# STM32MP25_CM0P register map
File version: 1.1
CPU: CM0PLUS r0p1, little endian, MPU, no FPU, vendor SysTick, 8 interrupt priority bits
Registers are 32-bit, read-write, reset 0x0 unless marked. A register's access mark holds for its fields unless they carry their own. Offsets are from the block's base; [hi:lo] are bit positions; {n}, {i} and the like mark numbered series; 'fields as' and 'values as' point back to an identical list; <NAME> marks a mode.

## LPDMA — LPDMA register block
Base 0x46210000
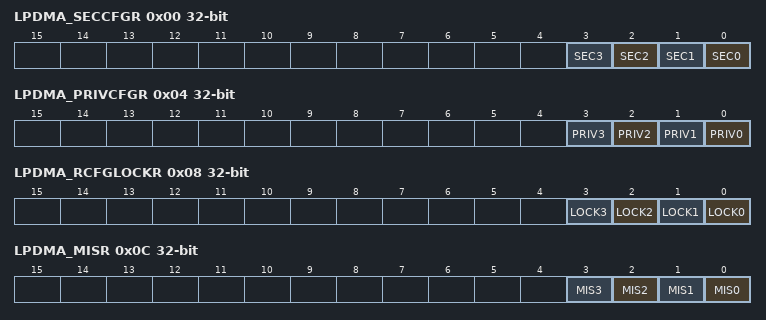
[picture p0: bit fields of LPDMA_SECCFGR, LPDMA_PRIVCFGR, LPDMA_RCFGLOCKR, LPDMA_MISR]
0x00 LPDMA_SECCFGR — LPDMA secure configuration register
  [all] fields
    0=nonsecure; 1=secure
  [n] SEC{n} (n=0..3) — secure state of channel x
0x04 LPDMA_PRIVCFGR — LPDMA privileged configuration register
  [all] fields
    0=unprivileged; 1=privileged
  [n] PRIV{n} (n=0..3) — privileged state of channel x
0x08 LPDMA_RCFGLOCKR — LPDMA configuration lock register
  [all] fields
    0=secure privilege and CID configuration of the channel x is writable; 1=secure privilege and CID configuration of the channel x is not writable
  [n] LOCK{n} (n=0..3) — lock the configuration of LPDMA_SECCFGR.SECx, LPDMA_PRIVCFGR.PRIVx, and LPDMA_CxCIDCFGR until a global DMA reset This bit is cleared after reset and, once set, it cannot be reset until a global DMA reset.
0x0C LPDMA_MISR ro — LPDMA nonsecure masked interrupt status register
  [all] fields
    0=no interrupt occurred on nonsecure channel x; 1=an interrupt occurred on nonsecure channel x
  [n] MIS{n} (n=0..3) — masked interrupt status of channel x
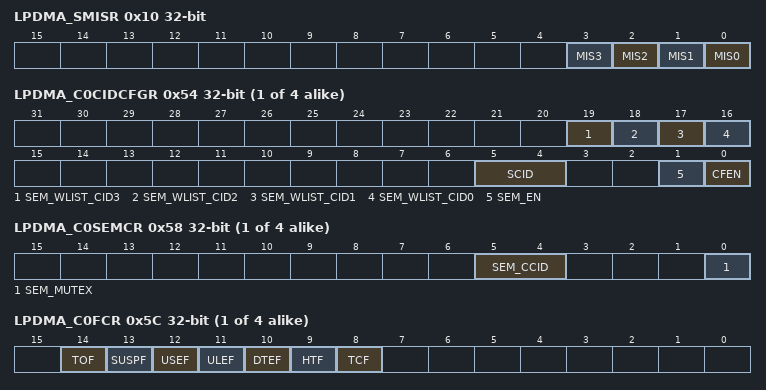
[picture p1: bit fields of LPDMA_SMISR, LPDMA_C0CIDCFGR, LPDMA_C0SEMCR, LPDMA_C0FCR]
0x10 LPDMA_SMISR ro — LPDMA secure masked interrupt status register
  [all] fields
    0=no interrupt occurred on the secure channel x; 1=an interrupt occurred on the secure channel x
  [n] MIS{n} (n=0..3) — masked interrupt status of the secure channel x
{0x50+0x80*i} LPDMA_C{i}LBAR (i=0..3) — LPDMA channel {i} linked-list base address register
  [31:16] LBA — linked-list base address of LPDMA channel x
{0x54+0x80*i} LPDMA_C{i}CIDCFGR (i=0..3) — LPDMA channel {i} CID register
  [19] SEM_WLIST_CID3 — white-listed CID3 in the CID allocation pool (of channel x in semaphoremode)
    0=CID3 black-listed in the CID allocation pool (of channel x in semaphore mode); 1=CID3 white-listed in the CID allocation pool (of channel x in semaphore mode)
  [18] SEM_WLIST_CID2 — white-listed CID2 in the CID allocation pool (of channel x in semaphoremode)
    0=CID2 black-listed in the CID allocation pool (of channel x in semaphore mode); 1=CID2 white-listed in the CID allocation pool (of channel x in semaphore mode)
  [17] SEM_WLIST_CID1 — white-listed CID1 in the CID allocation pool (of channel x in semaphoremode)
    0=CID1 black-listed in the CID allocation pool (of the channel x in semaphore mode); 1=CID1 white-listed in the CID allocation pool (of the channel x in semaphore mode)
  [16] SEM_WLIST_CID0 — white-listed CID0 in the CID allocation pool (of channel x in semaphoremode)
    0=CID0 black-listed in the CID allocation pool (of channel x in semaphore mode); 1=CID0 white-listed in the CID allocation pool (of channel x in semaphore mode)
  [5:4] SCID — static CID selection to channel x
    0=CID0 allocated to channel x; 1=CID1 allocated to channel x; 2=CID2 statically allocated to channel x; 3=CID3 allocated to channel x
  [1] SEM_EN — semaphore mode enable (for the CID allocation policy to the channel x) Note: If SEM_EN=1 and if a trusted domain or debug domain CID agent clears this bit, then the LPDMA hardware automatically clears the LPDMA_CxSEMCR.SEM_MUTEX.
    0=semaphore mode disabled. CID allocation policy to the channel x is defined by SCID[1:0].; 1=semaphore mode enabled. CID allocation policy to the channel x is defined by the white listed allocation pool SEM_WLIST_CIDx and LPDMA_CxSEMCR.SEM_MUTEX.
  [0] CFEN — CID filtering enable of the channel x Note: If SCFEN=1 and if a trusted domain or debug domain CID agent clears this bit, then the LPDMA hardware automatically clears the LPDMA_CxSEMCR.SEM_MUTEX.
    0=CID filtering disabled for when accessing a channel x register/field; 1=CID filtering enabled for when accessing a channel x register/field
{0x58+0x80*i} LPDMA_C{i}SEMCR (i=0..3) — LPDMA channel {i} semaphore control register
  [5:4] SEM_CCID ro — current CID allocated to channel x in semaphore mode This read-only field is internally updated when a white-listed CID takes the control of channel x, in semaphore mode. If SEM_MUTEX=0, this same CID also released it.
    0=CID0 is the last white-listed CID that took the control of channel x; 1=CID1 is the last white-listed CID that took the control of channel x; 2=CID2 is the last white-listed CID that took the control of channel x; 3=CID3 is the last white-listed CID that took the control of the channel x
  [0] SEM_MUTEX — mutex exclusion semaphore for the CID allocation of channel x (insemaphoremode) If the channel x is in secure state (LPDMA_SECCFGR.SECx=1), this bit can only be written by a secure agent. If the channel x is in privileged state (LPDMA_PRIVCFGR.PRIVx=1), this bit can only be written by a privileged agent. If the channel x is CID-filtered (LPDMA_CxCIDCFGR.CFEN=1) and in semaphore mode (LPDMA_CIDCFGR.SEM_EN=1), this bit can only be written either by an authorized (white-listed) CID agent to take the control, or by the same (white-listed) CID agent to release the control. Condition 'On write': Condition 'On read': Note: This bit must be written when LPDMA_CxCR.EN=0. This bit is read-only when LPDMA_CxCR.EN=1. Note: When EN of CFEN bit is cleared in LPDMA_CxSEMCR, the LPDMA hardware automatically clears this SEM_MUTEX bit.
    0=channel x CID-free (not currently under the control of any white-listed CID); 1=channel x CID-allocated (currently taken and under the control of one white-listed CID)
{0x5C+0x80*i} LPDMA_C{i}FCR wo (i=0..3) — LPDMA channel {i} flag clear register
  [14] TOF — trigger overrun flag clear
    0=no effect; 1=clears the corresponding TOF flag
  [13] SUSPF — completed suspension flag clear
    0=no effect; 1=corresponding SUSPF flag cleared
  [12] USEF — user setting error flag clear
    0=no effect; 1=corresponding USEF flag cleared
  [11] ULEF — update link transfer error flag clear
    0=no effect; 1=corresponding ULEF flag cleared
  [10] DTEF — data transfer error flag clear
    0=no effect; 1=corresponding DTEF flag cleared
  [9] HTF — half transfer flag clear
    0=no effect; 1=corresponding HTF flag cleared
  [8] TCF — transfer complete flag clear
    0=no effect; 1=corresponding TCF flag cleared
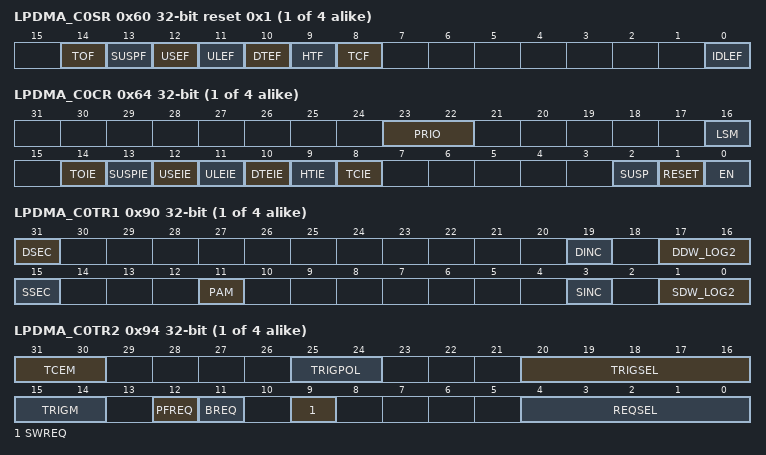
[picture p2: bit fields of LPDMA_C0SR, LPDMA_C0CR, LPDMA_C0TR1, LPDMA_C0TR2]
{0x60+0x80*i} LPDMA_C{i}SR ro reset 0x1 (i=0..3) — LPDMA channel {i} status register
  [14] TOF — trigger overrun flag clear
    0=no effect; 1=clears the corresponding TOF flag
  [13] SUSPF — completed suspension flag
    0=no completed suspension event; 1=a completed suspension event occurred
  [12] USEF — user setting error flag
    0=no user setting error event; 1=a user setting error event occurred
  [11] ULEF — update link transfer error flag
    0=no update link transfer error event; 1=a master bus error event occurred while updating a linked-list register from memory
  [10] DTEF — data transfer error flag
    0=no data transfer error event; 1=a master bus error event occurred on a data transfer
  [9] HTF — half transfer flag A half transfer event is a half block transfer that occurs when half of the bytes of the source block size (rounded-up integer of LPDMA_CxBR1.BNDT[15:0]/2) has been transferred to the destination.
    0=no half transfer event; 1=a half transfer event occurred
  [8] TCF — transfer complete flag A transfer complete event is a block transfer complete or a LLI transfer complete including the upload of the next LLI if any, or the full linked-list completion, depending on the transfer complete event mode LPDMA_CxTR2.TCEM[1:0].
    0=no transfer complete event; 1=a transfer complete event occurred
  [0] IDLEF — idle flag This idle flag is de-asserted by hardware when the channel is enabled (LPDMA_CxCR.EN=1) with a valid channel configuration (no USEF to be immediately reported). This idle flag is asserted after hard reset or by hardware when the channel is back in idle state (in suspended or disabled state).
    0=channel not in idle state; 1=channel in idle state
{0x64+0x80*i} LPDMA_C{i}CR (i=0..3) — LPDMA channel {i} control register
  [23:22] PRIO — priority level of the channel x LPDMA transfer versus others Note: This bit must be written when EN=0. This bit is read-only when EN=1.
    0=low priority, low weight; 1=low priority, mid weight; 2=low priority, high weight; 3=high priority
  [16] LSM — Link step mode First the block transfer is executed as defined by the current internal register file until LPDMA_CxBR1.BNDT[15:0]=0). Secondly the next linked-list data structure is conditionally uploaded from memory as defined by LPDMA_CxLLR. Then channel execution is completed. Note: This bit must be written when EN=0. This bit is read-only when EN=1.
    0=channel executed for the full linked-list and completed at the end of the last LLI (LPDMA_CxLLR=0). The 16 low-significant bits of the link address are null (LA[15:0]=0) and all the update bits are null (UT1=UB1=UT2=USA=UDA=ULL=0). Then LPDMA_CxBR1.BNDT[15:0]=0.; 1=channel executed once for the current LLI
  [14] TOIE — trigger overrun interrupt enable
    0=interrupt disabled; 1=interrupt enabled
  [13] SUSPIE — completed suspension interrupt enable
    0=interrupt disabled; 1=interrupt enabled
  [12] USEIE — user setting error interrupt enable
    0=interrupt disabled; 1=interrupt enabled
  [11] ULEIE — update link transfer error interrupt enable
    0=interrupt disabled; 1=interrupt enabled
  [10] DTEIE — data transfer error interrupt enable
    0=interrupt disabled; 1=interrupt enabled
  [9] HTIE — half transfer complete interrupt enable
    0=interrupt disabled; 1=interrupt enabled
  [8] TCIE — transfer complete interrupt enable
    0=interrupt disabled; 1=interrupt enabled
  [2] SUSP — suspend Writing 1 into the field RESET (bit 1) causes the hardware to de-assert this bit, whatever is written into this bit 2. Else: Software must write 1 in order to suspend an active channel (with an ongoing DMA transfer over its master ports). The software must write 0 in order to resume a suspended channel, following the programming sequence detailed in Figure178.
    0=write: resume channel, read: channel not suspended; 1=write: suspend channel, read: channel suspended
  [1] RESET wo — reset This bit is write only. Writing 0 has no impact. Writing 1 implies the reset of the following: the channel internal state, SUSP and EN bits (whatever is written receptively in bit 2 and bit 0). The reset is effective when the channel is in steady state, meaning one of the following: - active channel in suspended state (LPDMA_CxSR.SUSPF=1 and LPDMA_CxSR.IDLEF=LPDMA_CxCR.EN=1) - channel in disabled state (LPDMA_CxSR.IDLEF=1 and LPDMA_CxCR.EN=0). After writing a RESET, to continue using this channel, the user must explicitly reconfigure the channel including the hardware-modified configuration registers (LPDMA_CxBR1, LPDMA_CxSAR and LPDMA_CxDAR) before enabling again the channel (see the programming sequence in Figure179).
    0=no channel reset; 1=channel reset
  [0] EN — enable Writing 1 into the field RESET (bit 1) causes the hardware to de-assert this bit, whatever is written into this bit 0. Else: this bit is de-asserted by hardware when there is a transfer error (master bus error or user setting error) or when there is a channel transfer complete (channel ready to be configured, for example: if LSM = 1 at the end of a single execution of the LLI). Else, this bit can be asserted by software. Writing 0 into this EN bit is ignored.
    0=write: ignored, read: channel disabled; 1=write: enable channel, read: channel enabled
{0x90+0x80*i} LPDMA_C{i}TR1 (i=0..3) — LPDMA channel {i} transfer register 1
  [31] DSEC — security attribute of the LPDMA transfer to the destination If LPDMA_SECCFGR.SECx=1 and the access is secure: This is a secure register bit. This bit can only be read by a secure software. This bit must be written by a secure software when LPDMA_SECCFGR.SECx=1. A secure write is ignored when LPDMA_SECCFGR.SECx=0. When LPDMA_SECCFGR.SECx is de-asserted, this DSEC bit is also de-asserted by hardware (on a secure reconfiguration of the channel as nonsecure), and the LPDMA transfer to the destination is nonsecure.
    0=LPDMA transfer nonsecure; 1=LPDMA transfer secure
  [19] DINC — destination incrementing single The destination address, pointed by LPDMA_CxDAR, is kept constant after a single transfer, or is incremented by the offset value corresponding to a contiguous data after a single transfer.
    0=fixed single; 1=contiguously incremented single
  [17:16] DDW_LOG2 — binary logarithm of the destination data width of a single in bytes Setting a 8-byte data width causes a user setting error to be reported and none transfer is issued. Note: A destination single transfer must have an aligned address with its data width (start address LPDMA_CxDAR[2:0] versus DDW_LOG2[1:0]). Otherwise a user setting error is reported and none transfer is issued.
    0=byte; 1=half-word (2 bytes); 2=word (4 bytes); 3=user setting error reported and no transfer issued
  [15] SSEC — security attribute of the LPDMA transfer from the source If LPDMA_SECCFGR.SECx=1 and the access is secure: This is a secure register bit. This bit can only be read by a secure software. This bit must be written by a secure software when LPDMA_SECCFGR.SECx=1. A secure write is ignored when LPDMA_SECCFGR.SECx=0. When LPDMA_SECCFGR.SECx is de-asserted, this SSEC bit is also de-asserted by hardware (on a secure reconfiguration of the channel as nonsecure), and the LPDMA transfer from the source is nonsecure.
    0=LPDMA transfer nonsecure; 1=LPDMA transfer secure
  [11] PAM — padding/alignment mode If DDW_LOG2[1:0] = SDW_LOG2[1:0]: if the data width of a single destination transfer is equal to the data width of a single source transfer, this bit is ignored. Else, in the following enumerated values, the condition PAM_1 is when destination data width is higher that source data width, and the condition PAM_2 is when destination data width is higher than source data width.
    0=B_0x0_PAM_1 (source data is transferred as right aligned, padded with 0s up to the destination data width); 1=B_0x1_PAM_1 (source data is transferred as right aligned, sign extended up to the destination data width)
  [3] SINC — source incrementing single The source address, pointed by LPDMA_CxSAR, is kept constant after a single transfer or is incremented by the offset value corresponding to a contiguous data after a single transfer.
    0=fixed single; 1=contiguously incremented single
  [1:0] SDW_LOG2 — binary logarithm of the source data width of a single in bytes Setting a 8-byte data width causes a user setting error to be reported and none transfer is issued. a source block size must be a multiple of the source data width (LPDMA_CxBR1.BNDT[2:0] versus SDW_LOG2[1:0]). Otherwise, a user setting error is reported and no transfer is issued. Note: A source single transfer must have an aligned address with its data width (start address LPDMA_CxSAR[2:0] versus SDW_LOG2[1:0]). Otherwise, a user setting error is reported and none transfer is issued.
    values as DDW_LOG2
{0x94+0x80*i} LPDMA_C{i}TR2 (i=0..3) — LPDMA channel {i} transfer register 2
  [31:30] TCEM — transfer complete event mode These bits define the transfer granularity for the transfer complete and half transfer complete events generation. Note: If the initial LLI<sub>0 </sub>data transfer is null/void (directly programmed by the internal register file with LPDMA_CxBR1.BNDT[15:0]=0), then neither the complete transfer event nor the half transfer event is generated. Note: If the initial LLI<sub>0 </sub>data transfer is null/void (i.e. directly programmed by the internal register file with LPDMA_CxBR1.BNDT[15:0]= 0), then the half transfer event is not generated, and the transfer complete event is generated when is completed the loading of the LLI<sub>1</sub>.
    0=at block level (when LPDMA_CxBR1.BNDT[15:0]=0): the complete (and the half) transfer event is generated at the (respectively half of the) end of a block; 1=same as 00; 2=at LLI level: the complete transfer event is generated at the end of the LLI transfer, including the update of the LLI if any. The half transfer event is generated at the half of the LLI data transfer (the LLI data transfer being a block transfer), if any data transfer.; 3=at channel level: the complete transfer event is generated at the end of the last LLI transfer. The half transfer event is generated at the half of the data transfer of the last LLI. The last LLI updates the link address LPDMA_CxLLR.LA[15:2] to zero and clears all the LPDMA_CxLLR update bits (UT1, UT2, UB1, USA, UDA and ULL). If the channel transfer is continuous/infinite, no event is generated.
  [25:24] TRIGPOL — trigger event polarity These bits define the polarity of the selected trigger event input defined by TRIGSEL[4:0].
    0=no trigger (masked trigger event); 1=trigger on the rising edge; 2=trigger on the falling edge; 3=same as 00
  [20:16] TRIGSEL — trigger event input selection These bits select the trigger event input of the LPDMA transfer (as perSection27.3.6), with an active trigger event if TRIGPOL[1:0]=00.
  [15:14] TRIGM — trigger mode These bits define the transfer granularity for its conditioning by the trigger. If the channel x is enabled (LPDMA_CxCR.EN asserted) with TRIGPOL[1:0]=0b00 or 0b11, these TRIGM[1:0] bits are ignored. Else, a DMA transfer is conditioned by at least one trigger hit: The LPDMA monitoring of a trigger for channel x is started when the channel is enabled/loaded with a new active trigger configuration: rising or falling edge on a selected trigger (TRIGPOL[1:0]=0b01 or respectively TRIGPOL[1:0]=0b10). The monitoring of this trigger is kept active during the triggered and uncompleted (data or link) transfer; and if a new trigger is detected then, this hit is internally memorized to grant the next transfer, as long as the defined rising or falling edge is not modified, and the TRIGSEL[4:0] is not modified, and the channel is enabled. Transferring a next LLI<sub>n+1</sub> that updates the LPDMA_CxTR2 with a new value for any of TRIGSEL[4:0] or TRIGPOL[1:0], resets the monitoring, trashing the memorized hit of the formerly defined LLI<sub>n </sub>trigger. After a first new trigger hit<sub>n+1</sub> is memorized, if another second trigger hit<sub>n+2</sub> is detected and if the hit<sub>n</sub> triggered transfer is still not completed, hit<sub>n+2 </sub>is lost and not memorized, and a trigger overrun flag is reported (LPDMA_CxSR.TOF=1), an interrupt is generated if enabled (LPDMA_CxCR.TOIE=1). The channel is not automatically disabled by hardware due to a trigger overrun.
    0=at block level: the first single read of each block transfer is conditioned by one hit trigger; 1=same as 00; 2=at link level: a LLI link transfer is conditioned by one hit trigger. The LLI data transfer (if any) is not conditioned.; 3=at programmed single level: each programmed single read is conditioned by one hit trigger
  [12] PFREQ — Hardware request in peripheral flow control mode Important: If a given channel x is not implemented with this feature, this bit is reserved and PFREQ is not present (see Section27.3.5 for the list of the implemented channels with this feature. If the channel x is activated (LPDMA_CxCR.EN asserted) with SWREQ=1 (software request for a memory-to-memory transfer), this bit is ignored. Else:
    0=the selected hardware request is driven by a peripheral with a hardware request/acknowledge protocol in LPDMA control mode. The LPDMA is programmed with LPDMA_CxCBR1.BNDT[15:0] and this is internally used by the hardware for the block transfer completion.; 1=the selected hardware request is driven by a peripheral with a hardware request/acknowledge protocol in peripheral control mode. The LPDMA block transfer can be early completed by the peripheral itself (see Section27.3.5 for more details).
  [11] BREQ — block hardware request If the channel x is activated (LPDMA_CxCR.EN asserted) with SWREQ = 1 (software request for a memory-to-memory transfer), this bit is ignored. Else:
    0=the selected hardware request is driven by a peripheral with a hardware request/acknowledge protocol at a single level; 1=the selected hardware request is driven by a peripheral with a hardware request/acknowledge protocol at a block level (seeSection27.3.4)
  [9] SWREQ — software request This bit is internally taken into account when LPDMA_CxCR.EN is asserted.
    0=no software request. The selected hardware request REQSEL[4:0] is taken into account.; 1=software request for a memory-to-memory transfer. The default selected hardware request as per REQSEL[4:0] is ignored.
  [4:0] REQSEL — DMA hardware request selection These bits are ignored if channel x is activated (LPDMA_CxCR.EN asserted) with SWREQ=1 (software request for a memory-to-memory transfer). Else, the selected hardware request is internally taken into account as per Section27.3.3. The user must not assign a same input hardware request (same REQSEL[4:0] value) to different active DMA channels (LPDMA_CxCR.EN=1 and LPDMA_CxTR2.SWREQ=0 for these channels). DMA is not intended to hardware support the case of simultaneous enabled channels incorrectly configured with a same hardware peripheral request signal, and there is no user setting error reporting.
{0x98+0x80*i} LPDMA_C{i}BR1 (i=0..3) — LPDMA channel {i} block register 1
  [15:0] BNDT — block number of data bytes to transfer from the source Block size transferred from the source. When the channel is enabled, this field becomes read-only and is decremented, indicating the remaining number of data items in the current source block to be transferred. BNDT[15:0] is programmed in number of bytes, maximum source block size is 64Kbytes -1. Once the last data transfer is completed (BNDT[15:0]=0): - if LPDMA_CxLLR.UB1=1, this field is updated by the LLI in the memory. - if LPDMA_CxLLR.UB1=0 and if there is at least one non null Uxx update bit, this field is internally restored to the programmed value. - if all LPDMA_CxLLR.Uxx=0 and if LPDMA_CxLLR.LA[15:0]=0, this field is internally restored to the programmed value (infinite/continuous last LLI). - if LPDMA_CxLLR=0, this field is kept as zero following the last LLI data transfer. Note: A non-null source block size must be a multiple of the source data width (BNDT[2:0] versus LPDMA_CxTR1.SDW_LOG2[1:0]). Else a user setting error is reported and none transfer is issued.
{0x9C+0x80*i} LPDMA_C{i}SAR (i=0..3) — LPDMA channel {i} source address register
  [31:0] SA — source address This field is the pointer to the address from which the next data is read. During the channel activity, depending on the source addressing mode (LPDMA_CxTR1.SINC), this field is either kept fixed or incremented by the data width (LPDMA_CxTR1.SDW_LOG2[1:0]) after each single source data, reflecting the next address from which data is read. In linked-list mode, after a LLI data transfer is completed, this register is automatically updated by LPDMA from the memory, provided the LLI is set with LPDMA_CxLLR.USA=1. Note: A source address must be aligned with the programmed data width of a source single (SA[32:0] versus LPDMA_CxTR1.SDW_LOG2[1:0]). Else, a user setting error is reported and no transfer is issued.
{0xA0+0x80*i} LPDMA_C{i}DAR (i=0..3) — LPDMA channel {i} destination address register
  [31:0] DA — destination address This field is the pointer to the address from which the next data is written. During the channel activity, depending on the destination addressing mode (LPDMA_CxTR1.DINC), this field is kept fixed or incremented by the data width (LPDMA_CxTR1.DDW_LOG2[1:0]) after each single destination data, reflecting the next address from which data is written. In linked-list mode, after a LLI data transfer is completed, this register is automatically updated by DMA from the memory, provided the LLI is set with LPDMA_CxLLR.UDA=1. Note: A destination address must be aligned with the programmed data width of a destination single (DA[2:0] versus LPDMA_CxTR1.DDW_LOG2[1:0]). Else, a user setting error is reported and no transfer is issued.
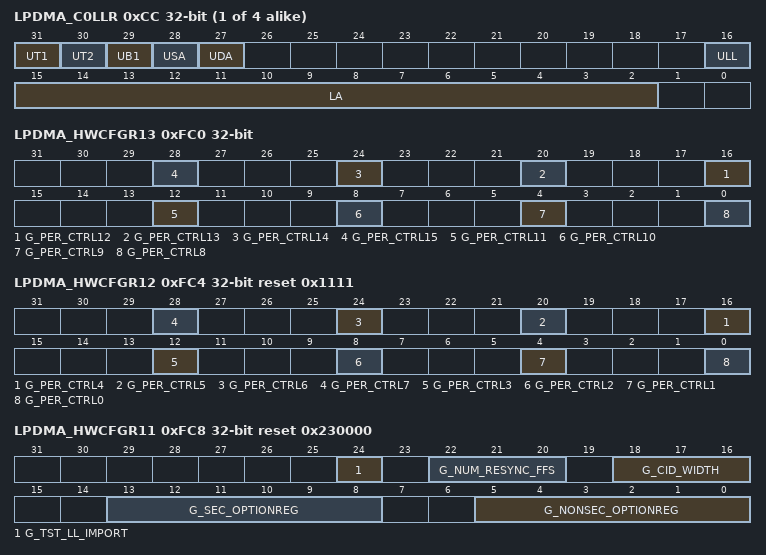
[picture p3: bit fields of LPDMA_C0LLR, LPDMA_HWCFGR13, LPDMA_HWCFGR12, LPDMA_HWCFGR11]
{0xCC+0x80*i} LPDMA_C{i}LLR (i=0..3) — LPDMA channel {i} linked-list address register
  [31] UT1 — Update LPDMA_CxTR1 from memory This bit controls the update of the LPDMA_CxTR1 register from the memory during the link transfer.
    0=no LPDMA_CxTR1 update; 1=LPDMA_CxTR1 update
  [30] UT2 — Update LPDMA_CxTR2 from memory This bit controls the update of the LPDMA_CxTR2 register from the memory during the link transfer.
    0=no LPDMA_CxTR2 update; 1=LPDMA_CxTR2 update
  [29] UB1 — Update LPDMA_CxBR1 from memory This bit controls the update of the LPDMA_CxBR1 register from the memory during the link transfer.
    0=no LPDMA_CxBR1 update from memory and internally restored to the previous programmed value; 1=LPDMA_CxBR1 update
  [28] USA — update LPDMA_CxSAR from memory This bit controls the update of the LPDMA_CxSAR register from the memory during the link transfer.
    0=no LPDMA_CxSAR update; 1=LPDMA_CxSAR update
  [27] UDA — Update LPDMA_CxDAR register from memory This bit is used to control the update of the LPDMA_CxDAR register from the memory during the link transfer.
    0=no LPDMA_CxDAR update; 1=LPDMA_CxDAR update
  [16] ULL — Update LPDMA_CxLLR register from memory This bit is used to control the update of the LPDMA_CxLLR register from the memory during the link transfer.
    0=no LPDMA_CxLLR update; 1=LPDMA_CxLLR update
  [15:2] LA — pointer (16-bit low-significant address) to the next linked-list data structure If UT1=UT2=UB1=USA=UDA=ULL=0 and if LA[15:2]=0, the current LLI is the last one. The channel transfer is completed without any update of the linked-list DMA register file. Else, this field is the pointer to the memory address offset from which the next linked-list data structure is automatically fetched from, once the data transfer is completed, in order to conditionally update the linked-list DMA internal register file (LPDMA_CxTR1, LPDMA_CxTR2, LPDMA_CxBR1, LPDMA_CxSAR, LPDMA_CxDAR and LPDMA_CxLLR). Note: The user must program the pointer to be 32-bit aligned. The two low-significant bits are write ignored.
0xFC0 LPDMA_HWCFGR13 ro — LPDMA hardware configuration 13 register
  [4n-32] G_PER_CTRL{n} (n=12..15) — DMA transfer type for channel {n}
    0=no peripheral flow control mode; 1=peripheral flow control mode allowed
  [12] G_PER_CTRL11 — DMA transfer type for channel 11
    0=no linked list mode; 1=linked-list mode allowed
  [8] G_PER_CTRL10 — DMA transfer type for channel 10
    values as G_PER_CTRL12
  [4] G_PER_CTRL9 — DMA transfer type for channel 9
    values as G_PER_CTRL12
  [0] G_PER_CTRL8 — DMA transfer type for channel 8
    values as G_PER_CTRL12
0xFC4 LPDMA_HWCFGR12 ro reset 0x1111 — LPDMA hardware configuration 12 register
  [4n] G_PER_CTRL{n} (n=4..7) — DMA transfer type for channel {n}
    values as LPDMA_HWCFGR13.G_PER_CTRL12
  [12] G_PER_CTRL3 — DMA transfer type for channel 3
    0=no linked list mode; 1=linked-list mode allowed
  [8] G_PER_CTRL2 — DMA transfer type for channel 2
    values as LPDMA_HWCFGR13.G_PER_CTRL12
  [4] G_PER_CTRL1 — DMA transfer type for channel 1
    values as LPDMA_HWCFGR13.G_PER_CTRL12
  [0] G_PER_CTRL0 — DMA transfer type for channel 0
    values as LPDMA_HWCFGR13.G_PER_CTRL12
0xFC8 LPDMA_HWCFGR11 ro reset 0x230000 — LPDMA hardware configuration 11 register
  [24] G_TST_LL_IMPORT — master port for the link transfer (DFT purpose only)
    0=port 0; 1=port 1
  [22:20] G_NUM_RESYNC_FFS — number of resynchronization flip-flops, in the range 2 to 6
  [18:16] G_CID_WIDTH — CID bus width, in the range of 1 to 4
  [13:8] G_SEC_OPTIONREG — secure optional register width, in the range of 0 to 32 1 to 32: n-bit width secure optional register
    0=no register
  [5:0] G_NONSEC_OPTIONREG — nonsecure optional register width, in the range of 0 to 32 1 to 32: n-bit width nonsecure optional register
    0=no register
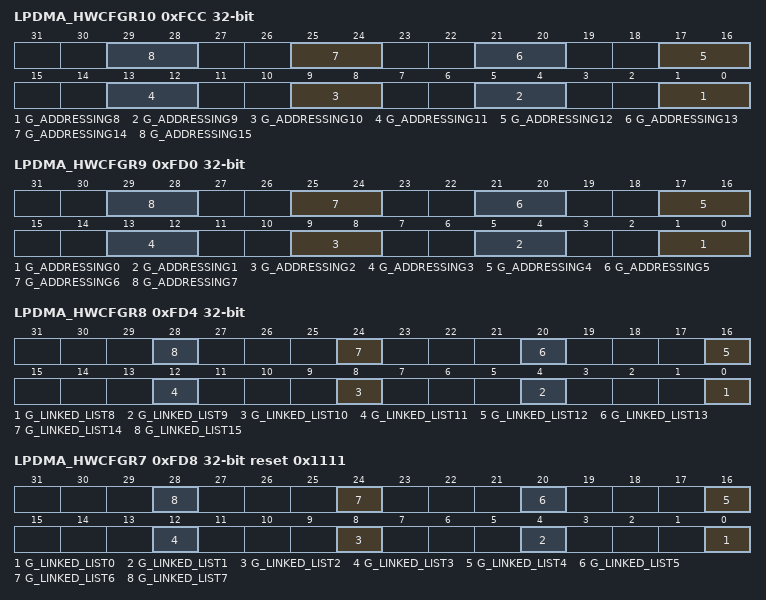
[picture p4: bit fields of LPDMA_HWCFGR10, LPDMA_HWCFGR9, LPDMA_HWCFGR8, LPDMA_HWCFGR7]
0xFCC LPDMA_HWCFGR10 ro — LPDMA hardware configuration 10 register
  [all] fields
    0=fixed/contiguous block addressing; 1=programmable 2D addressing
  [4n-31:4n-32] G_ADDRESSING{n} (n=8..15) — DMA transfers type for the channel {n}
0xFD0 LPDMA_HWCFGR9 ro — LPDMA hardware configuration 9 register
  [all] fields
    values as the fields of LPDMA_HWCFGR10
  [4n+1:4n] G_ADDRESSING{n} (n=0..7) — DMA transfers type for the channel {n}
0xFD4 LPDMA_HWCFGR8 ro — LPDMA hardware configuration 8 register
  [all] fields
    0=no linked-list mode; 1=linked-list mode allowed
  [4n-32] G_LINKED_LIST{n} (n=8..15) — DMA transfers type for the channel {n}
0xFD8 LPDMA_HWCFGR7 ro reset 0x1111 — LPDMA hardware configuration 7 register
  [all] fields
    0=no linked-list mode; 1=linked-list mode allowed
  [4n] G_LINKED_LIST{n} (n=0..7) — DMA transfers type for the channel {n}
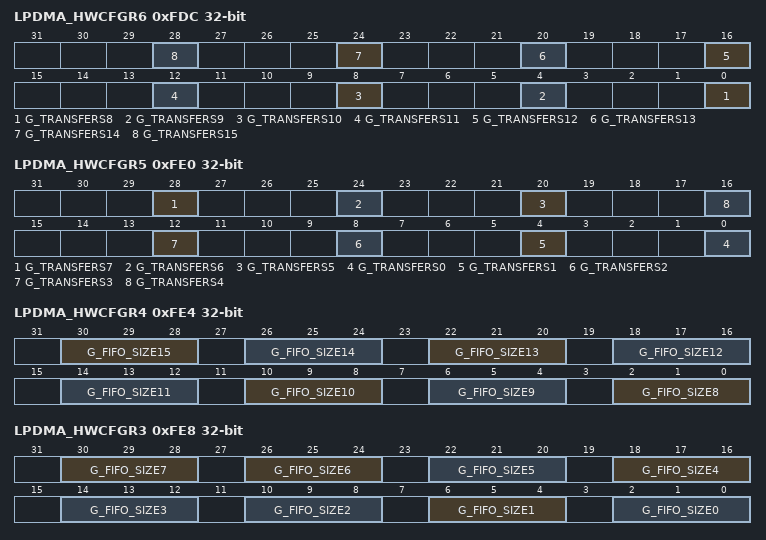
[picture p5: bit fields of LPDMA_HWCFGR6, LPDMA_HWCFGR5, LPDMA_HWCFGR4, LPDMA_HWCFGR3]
0xFDC LPDMA_HWCFGR6 ro — LPDMA hardware configuration 6 register
  [all] fields
    0=single only; 1=bursts and single
  [4n-32] G_TRANSFERS{n} (n=8..15) — DMA transfers type for the channel {n}
0xFE0 LPDMA_HWCFGR5 ro — LPDMA hardware configuration 5 register
  [all] fields
    0=single only; 1=bursts and single
  [28] G_TRANSFERS7 — DMA transfers type for the channel 7
  [24] G_TRANSFERS6 — DMA transfers type for the channel 6
  [20] G_TRANSFERS5 — DMA transfers type for the channel 6
  [4n] G_TRANSFERS{n} (n=0..4) — DMA transfers type for the channel {n}
0xFE4 LPDMA_HWCFGR4 ro — LPDMA hardware configuration 4 register
  [all] fields
    0=no FIFO. A single source transfer cell is internally registered.
  [30:28] G_FIFO_SIZE15 — FIFO size for the channel 15 (0 to 7) 1 to 7: FIFO of 2<sup>N+1</sup> bytes.
  [26:24] G_FIFO_SIZE14 — FIFO size for the channel 14 (0 to 7) 1 to 7: FIFO of 2<sup>N+1</sup> bytes.
  [22:20] G_FIFO_SIZE13 — FIFO size for the channel 13 (0 to 7) 1 to 7: FIFO of 2<sup>N+1</sup> bytes.
  [18:16] G_FIFO_SIZE12 — FIFO size for the channel 12 (0 to 7): 1 to 7: FIFO of 2<sup>N+1</sup> bytes.
  [4n-30:4n-32] G_FIFO_SIZE{n} (n=8..11) — FIFO size for the channel {n} (0 to 7) 1 to 7: FIFO of 2<sup>N+1</sup> bytes.
0xFE8 LPDMA_HWCFGR3 ro — LPDMA hardware configuration 3 register
  [all] fields
    values as the fields of LPDMA_HWCFGR4
  [30:28] G_FIFO_SIZE7 — FIFO size for the channel 7 (0 to 7) 1 to 7: FIFO of 2<sup>N+1</sup> bytes
  [4n+2:4n] G_FIFO_SIZE{n} (n=3..6) — FIFO size for the channel {n} (0 to 7) 1 to 7: FIFO of 2<sup>N+1</sup> bytes.
  [10:8] G_FIFO_SIZE2 — FIFO size for the channel 2 (0 to 7): 1 to 7: FIFO of 2<sup>N+1</sup> bytes.
  [6:4] G_FIFO_SIZE1 — FIFO size for the channel 1 (0 to 7) 1 to 7: FIFO of 2<sup>N+1</sup> bytes.
  [2:0] G_FIFO_SIZE0 — FIFO size for the channel 0 (0 to 7) 1 to 7: FIFO of 2<sup>N+1</sup> bytes.
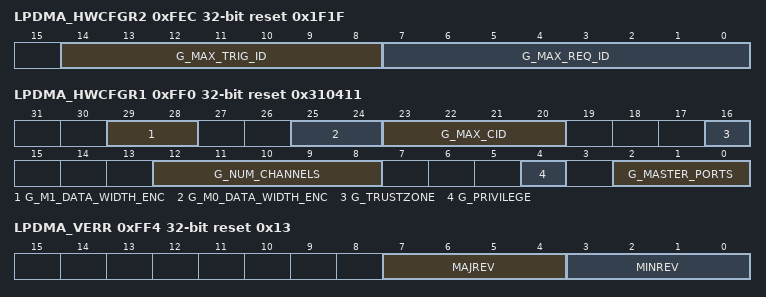
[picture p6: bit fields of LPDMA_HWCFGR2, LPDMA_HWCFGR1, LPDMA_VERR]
0xFEC LPDMA_HWCFGR2 ro reset 0x1F1F — LPDMA hardware configuration 2 register
  [14:8] G_MAX_TRIG_ID — maximum trigger event ID (0 to 127)
  [7:0] G_MAX_REQ_ID — maximum peripheral request ID (0 to 255)
0xFF0 LPDMA_HWCFGR1 ro reset 0x310411 — LPDMA hardware configuration 1 register
  [29:28] G_M1_DATA_WIDTH_ENC — master port 1 data bus width
    0=32-bit; 1=64-bit
  [25:24] G_M0_DATA_WIDTH_ENC — master port 0 data bus width
    0=32-bit; 1=64-bit
  [23:20] G_MAX_CID — maximum compartment ID (CID) 1 to 15: DMA CID-aware. Any channel is a separate CID-aware resource. Support of n+1 CIDs (from CID0 up to CIDn).
    0=no CID support, DMA not CID-aware
  [16] G_TRUSTZONE — TrustZone
    0=no TrustZone; 1=TrustZone support
  [12:8] G_NUM_CHANNELS — Number of DMA channels
  [4] G_PRIVILEGE
    0=no privilege; 1=privilege support
  [2:0] G_MASTER_PORTS — master ports type
    0=one AXI (AXI4); 1=one AHB: port 0 (AHB5)
0xFF4 LPDMA_VERR ro reset 0x13 — LPDMA version register
  [7:4] MAJREV — LPDMA major revision
  [3:0] MINREV — LPDMA minor revision
0xFF8 LPDMA_IPIDR ro reset 0x100003 — LPDMA identification register
  [31:0] ID — LPDMA identification
0xFFC LPDMA_SIDR ro — LPDMA size identification register
  [31:0] SID — Size identification

## Notices in the file
Copyright (c) 2025 STMicroelectronics.
SPDX-License-Identifier: Apache-2.0
Licensed under the Apache License, Version 2.0 (the "License");
you may not use this file except in compliance with the License.
You may obtain a copy of the License at
http://www.apache.org/licenses/LICENSE-2.0
Unless required by applicable law or agreed to in writing, software
distributed under the License is distributed on an "AS IS" BASIS,
WITHOUT WARRANTIES OR CONDITIONS OF ANY KIND, either express or implied.
See the License for the specific language governing permissions and
limitations under the License.
